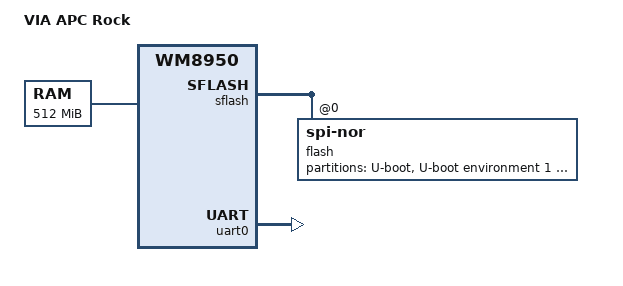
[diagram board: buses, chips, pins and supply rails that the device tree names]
// SPDX-License-Identifier: GPL-2.0-or-later
/*
 * Copyright (C) 2025 Alexey Charkov <alchark@gmail.com>
 */

/dts-v1/;
/include/ "wm8950.dtsi"

/ {
	model = "VIA APC Rock";
	compatible = "via,apc-rock", "wm,wm8950";

	memory@0 {
		device_type = "memory";
		reg = <0x0 0x20000000>;
	};
};

&sflash {
	status = "okay";

	flash@0 {
		compatible = "jedec,spi-nor";
		reg = <0>;

		partitions {
			compatible = "fixed-partitions";
			#address-cells = <1>;
			#size-cells = <1>;

			partition@0 {
				label = "U-boot";
				reg = <0 0x50000>;
				read-only;
			};

			partition@1 {
				label = "U-boot environment 1";
				reg = <0x50000 0x10000>;
			};

			partition@2 {
				label = "U-boot environment 2";
				reg = <0x60000 0x10000>;
			};

			partition@3 {
				label = "W-load";
				reg = <0x70000 0x10000>;
				read-only;
			};
		};
	};
};

&uart0 {
	status = "okay";
};
